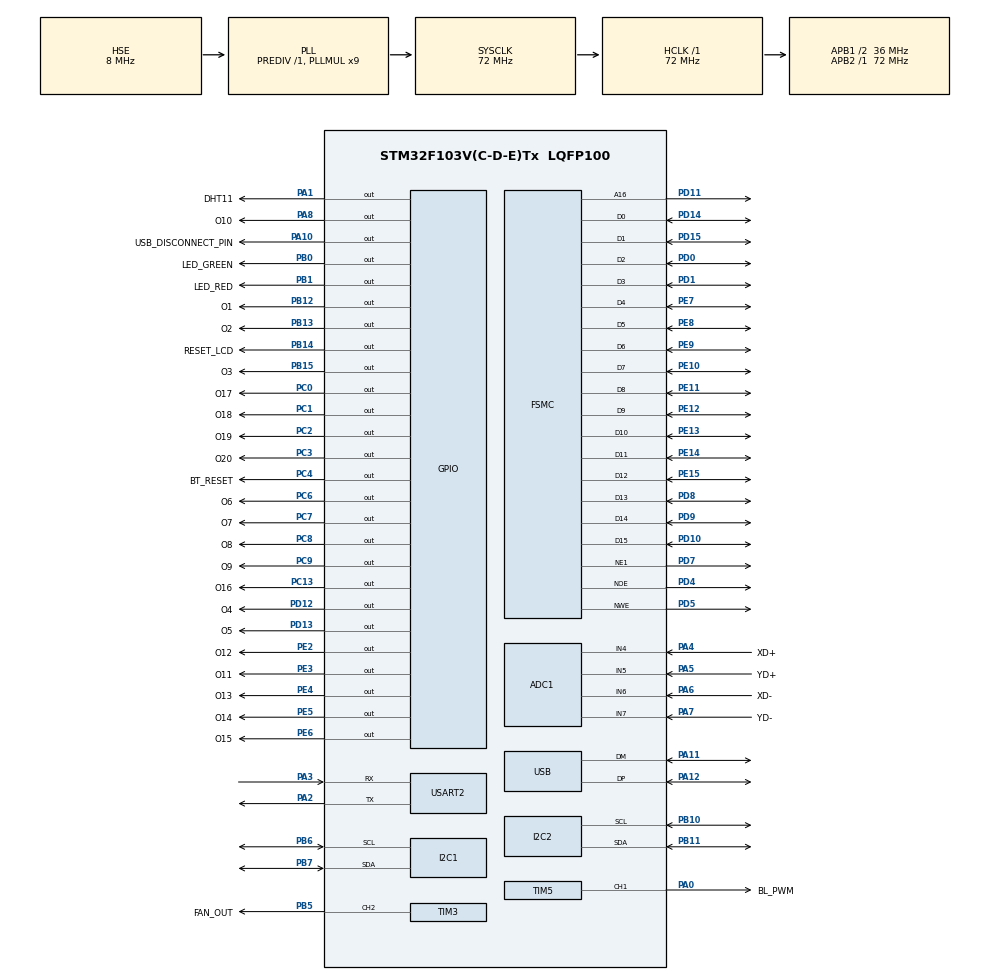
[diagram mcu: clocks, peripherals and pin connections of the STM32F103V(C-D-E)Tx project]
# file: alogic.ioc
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ADC1.Channel-0\#ChannelRegularConversion=ADC_CHANNEL_4
ADC1.ExternalTrigConv=ADC_EXTERNALTRIGCONV_T1_CC1
ADC1.NbrOfConversion=1
ADC1.NbrOfConversionFlag=1
ADC1.Rank-0\#ChannelRegularConversion=1
ADC1.SamplingTime-0\#ChannelRegularConversion=ADC_SAMPLETIME_1CYCLE_5
ADC1.master=1
Dma.ADC1.0.Direction=DMA_PERIPH_TO_MEMORY
Dma.ADC1.0.Instance=DMA1_Channel1
Dma.ADC1.0.MemDataAlignment=DMA_MDATAALIGN_HALFWORD
Dma.ADC1.0.MemInc=DMA_MINC_ENABLE
Dma.ADC1.0.Mode=DMA_CIRCULAR
Dma.ADC1.0.PeriphDataAlignment=DMA_PDATAALIGN_HALFWORD
Dma.ADC1.0.PeriphInc=DMA_PINC_DISABLE
Dma.ADC1.0.Priority=DMA_PRIORITY_VERY_HIGH
Dma.Request0=ADC1
FSMC.AddressSetupTime1=2
FSMC.BusTurnAroundDuration1=0
FSMC.DataSetupTime1=2
FSMC.ExtendedMode1=FSMC_EXTENDED_MODE_DISABLE
IWDG.Prescaler=IWDG_PRESCALER_64
IWDG.Reload=4000
Mcu.Family=STM32F1
Mcu.Name=STM32F103V(C-D-E)Tx
Mcu.Package=LQFP100
NVIC.DMA1_Channel1_IRQn=true\:14\:0\:true\:false\:true\:false\:true
NVIC.I2C1_ER_IRQn=true\:1\:0\:true\:false\:true\:true\:true
NVIC.I2C1_EV_IRQn=true\:0\:0\:false\:false\:true\:true\:true
NVIC.I2C2_ER_IRQn=true\:1\:0\:true\:false\:true\:true\:true
NVIC.I2C2_EV_IRQn=true\:0\:0\:false\:false\:true\:true\:true
NVIC.PriorityGroup=NVIC_PRIORITYGROUP_4
NVIC.RCC_IRQn=true\:0\:0\:false\:false\:true\:true\:false
NVIC.RTC_IRQn=true\:0\:0\:false\:false\:true\:true\:true
NVIC.TIM2_IRQn=true\:4\:0\:true\:false\:true\:true\:true
NVIC.TIM4_IRQn=true\:11\:0\:true\:false\:true\:true\:true
NVIC.TIM7_IRQn=true\:13\:0\:true\:false\:true\:true\:true
NVIC.TIM8_UP_IRQn=true\:10\:0\:true\:false\:true\:true\:true
NVIC.USART2_IRQn=true\:5\:0\:true\:false\:true\:true\:true
NVIC.USB_LP_CAN1_RX0_IRQn=true\:0\:0\:false\:false\:true\:false\:true
OSC_IN.Mode=HSE-External-Oscillator
OSC_IN.Signal=RCC_OSC_IN
OSC_OUT.Mode=HSE-External-Oscillator
OSC_OUT.Signal=RCC_OSC_OUT
PA0-WKUP.GPIO_Label=BL_PWM
PA0-WKUP.Signal=S_TIM5_CH1
PA1.GPIO_Label=DHT11
PA1.GPIO_ModeDefaultOutputPP=GPIO_MODE_OUTPUT_OD
PA1.GPIO_PuPd=GPIO_PULLUP
PA1.PinState=GPIO_PIN_SET
PA1.Signal=GPIO_Output
PA10.GPIO_Label=USB_DISCONNECT_PIN
PA10.Signal=GPIO_Output
PA11.Mode=Device
PA11.Signal=USB_DM
PA12.Mode=Device
PA12.Signal=USB_DP
PA13.Mode=Serial_Wire
PA13.Signal=SYS_JTMS-SWDIO
PA14.Mode=Serial_Wire
PA14.Signal=SYS_JTCK-SWCLK
PA2.Mode=Asynchronous
PA2.Signal=USART2_TX
PA3.Mode=Asynchronous
PA3.Signal=USART2_RX
PA4.GPIO_Label=XD+
PA4.Signal=ADCx_IN4
PA5.GPIO_Label=YD+
PA5.Signal=ADCx_IN5
PA6.GPIO_Label=XD-
PA6.Signal=ADCx_IN6
PA7.GPIO_Label=YD-
PA7.Signal=ADCx_IN7
PA8.GPIO_Label=O10
PA8.Signal=GPIO_Output
PB0.GPIO_Label=LED_GREEN
PB0.Signal=GPIO_Output
PB1.GPIO_Label=LED_RED
PB1.Signal=GPIO_Output
PB10.Mode=I2C
PB10.Signal=I2C2_SCL
PB11.Mode=I2C
PB11.Signal=I2C2_SDA
PB12.GPIO_Label=O1
PB12.Signal=GPIO_Output
PB13.GPIO_Label=O2
PB13.Signal=GPIO_Output
PB14.GPIO_Label=RESET_LCD
PB14.Signal=GPIO_Output
PB15.GPIO_Label=O3
PB15.Signal=GPIO_Output
PB5.GPIO_Label=FAN_OUT
PB5.Signal=S_TIM3_CH2
PB6.Mode=I2C
PB6.Signal=I2C1_SCL
PB7.Mode=I2C
PB7.Signal=I2C1_SDA
PC0.GPIO_Label=O17
PC0.Signal=GPIO_Output
PC1.GPIO_Label=O18
PC1.Signal=GPIO_Output
PC13-TAMPER-RTC.GPIO_Label=O16
PC13-TAMPER-RTC.Signal=GPIO_Output
PC14-OSC32_IN.Mode=LSE-External-Oscillator
PC14-OSC32_IN.Signal=RCC_OSC32_IN
PC15-OSC32_OUT.Mode=LSE-External-Oscillator
PC15-OSC32_OUT.Signal=RCC_OSC32_OUT
PC2.GPIO_Label=O19
PC2.Signal=GPIO_Output
PC3.GPIO_Label=O20
PC3.Signal=GPIO_Output
PC4.GPIO_Label=BT_RESET
PC4.Signal=GPIO_Output
PC6.GPIO_Label=O6
PC6.Signal=GPIO_Output
PC7.GPIO_Label=O7
PC7.Signal=GPIO_Output
PC8.GPIO_Label=O8
PC8.Signal=GPIO_Output
PC9.GPIO_Label=O9
PC9.Signal=GPIO_Output
PD0.Mode=16b-d1
PD0.Signal=FSMC_D2
PD1.Mode=16b-d1
PD1.Signal=FSMC_D3
PD10.Mode=16b-d1
PD10.Signal=FSMC_D15
PD11.Mode=A16_1
PD11.Signal=FSMC_A16
PD12.GPIO_Label=O4
PD12.Signal=GPIO_Output
PD13.GPIO_Label=O5
PD13.Signal=GPIO_Output
PD14.Mode=16b-d1
PD14.Signal=FSMC_D0
PD15.Mode=16b-d1
PD15.Signal=FSMC_D1
PD4.Mode=Lcd1
PD4.Signal=FSMC_NOE
PD5.Mode=Lcd1
PD5.Signal=FSMC_NWE
PD7.Mode=NorPsramChipSelect1_1
PD7.Signal=FSMC_NE1
PD8.Mode=16b-d1
PD8.Signal=FSMC_D13
PD9.Mode=16b-d1
PD9.Signal=FSMC_D14
PE10.Mode=16b-d1
PE10.Signal=FSMC_D7
PE11.Mode=16b-d1
PE11.Signal=FSMC_D8
PE12.Mode=16b-d1
PE12.Signal=FSMC_D9
PE13.Mode=16b-d1
PE13.Signal=FSMC_D10
PE14.Mode=16b-d1
PE14.Signal=FSMC_D11
PE15.Mode=16b-d1
PE15.Signal=FSMC_D12
PE2.GPIO_Label=O12
PE2.Signal=GPIO_Output
PE3.GPIO_Label=O11
PE3.Signal=GPIO_Output
PE4.GPIO_Label=O13
PE4.Signal=GPIO_Output
PE5.GPIO_Label=O14
PE5.Signal=GPIO_Output
PE6.GPIO_Label=O15
PE6.Signal=GPIO_Output
PE7.Mode=16b-d1
PE7.Signal=FSMC_D4
PE8.Mode=16b-d1
PE8.Signal=FSMC_D5
PE9.Mode=16b-d1
PE9.Signal=FSMC_D6
ProjectManager.HeapSize=0x200
ProjectManager.StackSize=0x400
ProjectManager.TargetToolchain=Makefile
RCC.ADCPresc=RCC_ADCPCLK2_DIV6
RCC.AHBFreq_Value=72000000
RCC.APB1CLKDivider=RCC_HCLK_DIV2
RCC.APB1Freq_Value=36000000
RCC.APB1TimFreq_Value=72000000
RCC.APB2Freq_Value=72000000
RCC.APB2TimFreq_Value=72000000
RCC.HCLKFreq_Value=72000000
RCC.PLLMUL=RCC_PLL_MUL9
RCC.PLLSourceVirtual=RCC_PLLSOURCE_HSE
RCC.RTCClockSelection=RCC_RTCCLKSOURCE_LSE
RCC.SYSCLKFreq_VALUE=72000000
RCC.SYSCLKSource=RCC_SYSCLKSOURCE_PLLCLK
RCC.USBFreq_Value=48000000
RCC.USBPrescaler=RCC_USBCLKSOURCE_PLL_DIV1_5
RTC.AutoPrediv=RTC_AUTO_1_SECOND
SH.ADCx_IN4.0=ADC1_IN4,IN4
SH.ADCx_IN5.0=ADC1_IN5,IN5
SH.ADCx_IN6.0=ADC1_IN6,IN6
SH.ADCx_IN7.0=ADC1_IN7,IN7
SH.S_TIM3_CH2.0=TIM3_CH2,PWM Generation2 CH2
SH.S_TIM5_CH1.0=TIM5_CH1,PWM Generation1 CH1
TIM1.AutoReloadPreload=TIM_AUTORELOAD_PRELOAD_ENABLE
TIM1.Period=200
TIM1.Prescaler=300
TIM1.TIM_MasterOutputTrigger=TIM_TRGO_OC1REF
TIM2.Period=1999
TIM2.Prescaler=35
TIM3.AutoReloadPreload=TIM_AUTORELOAD_PRELOAD_ENABLE
TIM3.Channel-PWM\ Generation2\ CH2=TIM_CHANNEL_2
TIM3.Period=500
TIM3.Pulse-PWM\ Generation2\ CH2=500
TIM4.AutoReloadPreload=TIM_AUTORELOAD_PRELOAD_ENABLE
TIM4.Period=1999
TIM4.Prescaler=7199
TIM5.AutoReloadPreload=TIM_AUTORELOAD_PRELOAD_ENABLE
TIM5.Channel-PWM\ Generation1\ CH1=TIM_CHANNEL_1
TIM5.Period=72
TIM5.Prescaler=9
TIM5.Pulse-PWM\ Generation1\ CH1=1
TIM7.AutoReloadPreload=TIM_AUTORELOAD_PRELOAD_ENABLE
TIM7.Period=239
TIM7.Prescaler=40000
TIM8.AutoReloadPreload=TIM_AUTORELOAD_PRELOAD_ENABLE
TIM8.Period=500
TIM8.Prescaler=7200
TIM8.TIM_MasterOutputTrigger=TIM_TRGO_UPDATE
USART2.VirtualMode=VM_ASYNC
USB.low_power_enable=DISABLE
USB_DEVICE.CLASS_NAME_FS=CDC
USB_DEVICE.MANUFACTURER_STRING=NeilLab
USB_DEVICE.PRODUCT_STRING_CDC_FS=Alogic Device 4.0
USB_DEVICE.VirtualMode=Cdc
USB_DEVICE.VirtualModeFS=Cdc_FS
VP_IWDG_VS_IWDG.Mode=IWDG_Activate
VP_RTC_VS_RTC_Activate.Mode=RTC_Enabled
VP_RTC_VS_RTC_Calendar.Mode=RTC_Calendar
VP_TIM1_VS_ClockSourceINT.Mode=Internal
VP_TIM2_VS_ClockSourceINT.Mode=Internal
VP_TIM3_VS_ClockSourceINT.Mode=Internal
VP_TIM4_VS_ClockSourceINT.Mode=Internal
VP_TIM5_VS_ClockSourceINT.Mode=Internal
VP_TIM7_VS_ClockSourceINT.Mode=Enable_Timer
VP_TIM8_VS_ClockSourceINT.Mode=Internal
VP_USB_DEVICE_VS_USB_DEVICE_CDC_FS.Mode=CDC_FS
board=custom

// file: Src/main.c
/* USER CODE BEGIN Header */
/**
  ******************************************************************************
  * @file           : main.c
  * @brief          : Main program body
  ******************************************************************************
  * @attention
  *
  * <h2><center>&copy; Copyright (c) 2019 STMicroelectronics.
  * All rights reserved.</center></h2>
  *
  * This software component is licensed by ST under Ultimate Liberty license
  * SLA0044, the "License"; You may not use this file except in compliance with
  * the License. You may obtain a copy of the License at:
  *                             www.st.com/SLA0044
  *
  ******************************************************************************
  */
/* USER CODE END Header */

#include "main.h"
#include "adc.h"
#include "dma.h"
#include "i2c.h"
#include "iwdg.h"
#include "rtc.h"
#include "tim.h"
#include "usart.h"
#include "usb_device.h"
#include "gpio.h"
#include "fsmc.h"

/* USER CODE BEGIN Includes */
#include "user_main.h"
/* USER CODE END Includes */

void SystemClock_Config(void);

int main(void)
{

  /* MCU Configuration--------------------------------------------------------*/

  /* Reset of all peripherals, Initializes the Flash interface and the Systick. */
  HAL_Init();

  /* Configure the system clock */
  SystemClock_Config();

  /* Initialize all configured peripherals */
  MX_GPIO_Init();
  MX_DMA_Init();
  MX_ADC1_Init();
  MX_USART2_UART_Init();
  MX_FSMC_Init();
  MX_I2C1_Init();
  MX_I2C2_Init();
  MX_RTC_Init();
  MX_TIM1_Init();
  MX_TIM2_Init();
  MX_TIM3_Init();
  MX_TIM4_Init();
  MX_TIM5_Init();
  MX_TIM7_Init();
  MX_TIM8_Init();
  MX_USB_DEVICE_Init();
  MX_IWDG_Init();
  /* USER CODE BEGIN 2 */

  // user_main();

  /* USER CODE END 2 */

  /* Infinite loop */
  while (1)
  {

  }
}

void SystemClock_Config(void)
{
  RCC_OscInitTypeDef RCC_OscInitStruct = {0};
  RCC_ClkInitTypeDef RCC_ClkInitStruct = {0};
  RCC_PeriphCLKInitTypeDef PeriphClkInit = {0};

  /** Initializes the CPU, AHB and APB busses clocks
  */
  RCC_OscInitStruct.OscillatorType = RCC_OSCILLATORTYPE_LSI|RCC_OSCILLATORTYPE_HSE
                              |RCC_OSCILLATORTYPE_LSE;
  RCC_OscInitStruct.HSEState = RCC_HSE_ON;
  RCC_OscInitStruct.HSEPredivValue = RCC_HSE_PREDIV_DIV1;
  RCC_OscInitStruct.LSEState = RCC_LSE_ON;
  RCC_OscInitStruct.HSIState = RCC_HSI_ON;
  RCC_OscInitStruct.LSIState = RCC_LSI_ON;
  RCC_OscInitStruct.PLL.PLLState = RCC_PLL_ON;
  RCC_OscInitStruct.PLL.PLLSource = RCC_PLLSOURCE_HSE;
  RCC_OscInitStruct.PLL.PLLMUL = RCC_PLL_MUL9;
  if (HAL_RCC_OscConfig(&RCC_OscInitStruct) != HAL_OK)
  {
    Error_Handler();
  }
  /** Initializes the CPU, AHB and APB busses clocks
  */
  RCC_ClkInitStruct.ClockType = RCC_CLOCKTYPE_HCLK|RCC_CLOCKTYPE_SYSCLK
                              |RCC_CLOCKTYPE_PCLK1|RCC_CLOCKTYPE_PCLK2;
  RCC_ClkInitStruct.SYSCLKSource = RCC_SYSCLKSOURCE_PLLCLK;
  RCC_ClkInitStruct.AHBCLKDivider = RCC_SYSCLK_DIV1;
  RCC_ClkInitStruct.APB1CLKDivider = RCC_HCLK_DIV2;
  RCC_ClkInitStruct.APB2CLKDivider = RCC_HCLK_DIV1;

  if (HAL_RCC_ClockConfig(&RCC_ClkInitStruct, FLASH_LATENCY_2) != HAL_OK)
  {
    Error_Handler();
  }
  PeriphClkInit.PeriphClockSelection = RCC_PERIPHCLK_RTC|RCC_PERIPHCLK_ADC
                              |RCC_PERIPHCLK_USB;
  PeriphClkInit.RTCClockSelection = RCC_RTCCLKSOURCE_LSE;
  PeriphClkInit.AdcClockSelection = RCC_ADCPCLK2_DIV6;
  PeriphClkInit.UsbClockSelection = RCC_USBCLKSOURCE_PLL_DIV1_5;
  if (HAL_RCCEx_PeriphCLKConfig(&PeriphClkInit) != HAL_OK)
  {
    Error_Handler();
  }
}

void Error_Handler(void)
{
}

/************************ (C) COPYRIGHT STMicroelectronics *****END OF FILE****/
